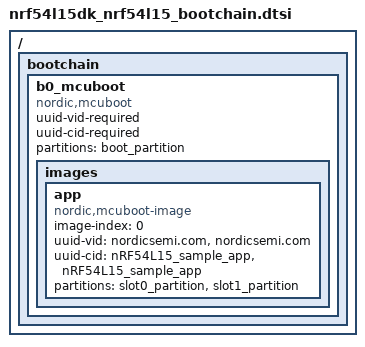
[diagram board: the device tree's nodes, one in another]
/*
 * Copyright (c) 2026 Nordic Semiconductor ASA
 *
 * SPDX-License-Identifier: LicenseRef-Nordic-5-Clause
 */

/ {
	bootchain {
		b0_mcuboot {
			compatible = "nordic,mcuboot";
			uuid-vid-required;
			uuid-cid-required;
			partitions = <&boot_partition>;

			images {
				app {
					compatible = "nordic,mcuboot-image";
					image-index = <0>;
					uuid-vid = "nordicsemi.com", "nordicsemi.com";
					uuid-cid = "nRF54L15_sample_app", "nRF54L15_sample_app";
					partitions = <&slot0_partition &slot1_partition>;
				};
			};
		};
	};
};
